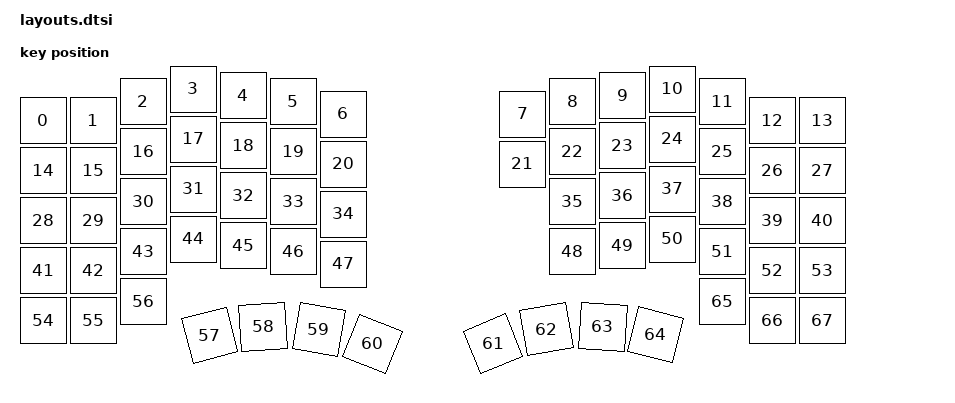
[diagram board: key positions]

#include <physical_layouts.dtsi>
/ {
    physical_layout0: physical_layout0 {
        compatible = "zmk,physical-layout";
        display-name = "Layout";
        keys
            = <&key_physical_attrs 100 100 50 88 0 0 0>
			,<&key_physical_attrs 100 100 150 88 0 0 0>
			,<&key_physical_attrs 100 100 250 50 0 0 0>
			,<&key_physical_attrs 100 100 350 25 0 0 0>
			,<&key_physical_attrs 100 100 450 38 0 0 0>
			,<&key_physical_attrs 100 100 550 50 0 0 0>
			,<&key_physical_attrs 100 100 650 75 0 0 0>
			,<&key_physical_attrs 100 100 1009 75 0 0 0>
			,<&key_physical_attrs 100 100 1109 50 0 0 0>
			,<&key_physical_attrs 100 100 1209 38 0 0 0>
			,<&key_physical_attrs 100 100 1309 25 0 0 0>
			,<&key_physical_attrs 100 100 1409 50 0 0 0>
			,<&key_physical_attrs 100 100 1509 88 0 0 0>
			,<&key_physical_attrs 100 100 1609 88 0 0 0>
			,<&key_physical_attrs 100 100 50 188 0 0 0>
			,<&key_physical_attrs 100 100 150 188 0 0 0>
			,<&key_physical_attrs 100 100 250 150 0 0 0>
			,<&key_physical_attrs 100 100 350 125 0 0 0>
			,<&key_physical_attrs 100 100 450 138 0 0 0>
			,<&key_physical_attrs 100 100 550 150 0 0 0>
			,<&key_physical_attrs 100 100 650 175 0 0 0>
			,<&key_physical_attrs 100 100 1009 175 0 0 0>
			,<&key_physical_attrs 100 100 1109 150 0 0 0>
			,<&key_physical_attrs 100 100 1209 138 0 0 0>
			,<&key_physical_attrs 100 100 1309 125 0 0 0>
			,<&key_physical_attrs 100 100 1409 150 0 0 0>
			,<&key_physical_attrs 100 100 1509 188 0 0 0>
			,<&key_physical_attrs 100 100 1609 188 0 0 0>
			,<&key_physical_attrs 100 100 50 288 0 0 0>
			,<&key_physical_attrs 100 100 150 288 0 0 0>
			,<&key_physical_attrs 100 100 250 250 0 0 0>
			,<&key_physical_attrs 100 100 350 225 0 0 0>
			,<&key_physical_attrs 100 100 450 238 0 0 0>
			,<&key_physical_attrs 100 100 550 250 0 0 0>
			,<&key_physical_attrs 100 100 650 275 0 0 0>
			,<&key_physical_attrs 100 100 1109 250 0 0 0>
			,<&key_physical_attrs 100 100 1209 238 0 0 0>
			,<&key_physical_attrs 100 100 1309 225 0 0 0>
			,<&key_physical_attrs 100 100 1409 250 0 0 0>
			,<&key_physical_attrs 100 100 1509 288 0 0 0>
			,<&key_physical_attrs 100 100 1609 288 0 0 0>
			,<&key_physical_attrs 100 100 50 388 0 0 0>
			,<&key_physical_attrs 100 100 150 388 0 0 0>
			,<&key_physical_attrs 100 100 250 350 0 0 0>
			,<&key_physical_attrs 100 100 350 325 0 0 0>
			,<&key_physical_attrs 100 100 450 338 0 0 0>
			,<&key_physical_attrs 100 100 550 350 0 0 0>
			,<&key_physical_attrs 100 100 650 375 0 0 0>
			,<&key_physical_attrs 100 100 1109 350 0 0 0>
			,<&key_physical_attrs 100 100 1209 338 0 0 0>
			,<&key_physical_attrs 100 100 1309 325 0 0 0>
			,<&key_physical_attrs 100 100 1409 350 0 0 0>
			,<&key_physical_attrs 100 100 1509 388 0 0 0>
			,<&key_physical_attrs 100 100 1609 388 0 0 0>
			,<&key_physical_attrs 100 100 50 488 0 0 0>
			,<&key_physical_attrs 100 100 150 488 0 0 0>
			,<&key_physical_attrs 100 100 250 450 0 0 0>
			,<&key_physical_attrs 100 100 373 531 (-1400) 373 531>
			,<&key_physical_attrs 100 100 487 504 (-400) 487 504>
			,<&key_physical_attrs 100 100 611 498 1000 611 498>
			,<&key_physical_attrs 100 100 731 520 2200 731 520>
			,<&key_physical_attrs 100 100 935 557 (-2200) 935 557>
			,<&key_physical_attrs 100 100 1049 515 (-1000) 1049 515>
			,<&key_physical_attrs 100 100 1173 497 400 1173 497>
			,<&key_physical_attrs 100 100 1289 506 1400 1289 506>
			,<&key_physical_attrs 100 100 1409 450 0 0 0>
			,<&key_physical_attrs 100 100 1509 488 0 0 0>
			,<&key_physical_attrs 100 100 1609 488 0 0 0>
            ;
    };
};
    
